AUTOSAR XML (schema 00051)
package /Components
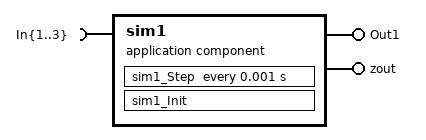
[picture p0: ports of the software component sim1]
  application sw component type sim1
    require port In{1..3}: nonqueued-receiver-com-spec{data-element=In{1..3}, init-value=0}, required-interface=In{1..3}
    provide port Out1: nonqueued-sender-com-spec{data-element=Out1, init-value=0}, provided-interface=Out1
    provide port zout: nonqueued-sender-com-spec{data-element=zout, init-value=0}, provided-interface=zout
    behavior sim1_IB: handle-termination-and-restart=NO-SUPPORT
      timing event Event_sim1_Step: start-on-event=sim1_Step, period=0.001
      runnable sim1_Init
      runnable sim1_Step
        data-read-access:
          access IN_In{1..3}_In{1..3}: accessed-variable=In{1..3}.In{1..3}
        data-write-access:
          access OUT_Out1_Out1: accessed-variable=Out1.Out1
          access OUT_zout_zout: accessed-variable=zout.zout
